# psoc4200bl register map
Vendor: Cypress Semiconductor; Series: PSoC4200BL; File version: 1.0
CPU: CM0 r0p1, little endian, no MPU, no FPU, 2 interrupt priority bits
Registers are 32-bit, read-write, reset 0x0 unless marked. A register's access mark holds for its fields unless they carry their own. Offsets are from the block's base; [hi:lo] are bit positions; lines under a group give offsets from that group.

## BLE (part 5 of 5) — Bluetooth Low Energy Subsystem
Base 0x402E0000
0xF000 BLESS group — Bluetooth Low Energy Subsystem Miscellaneous
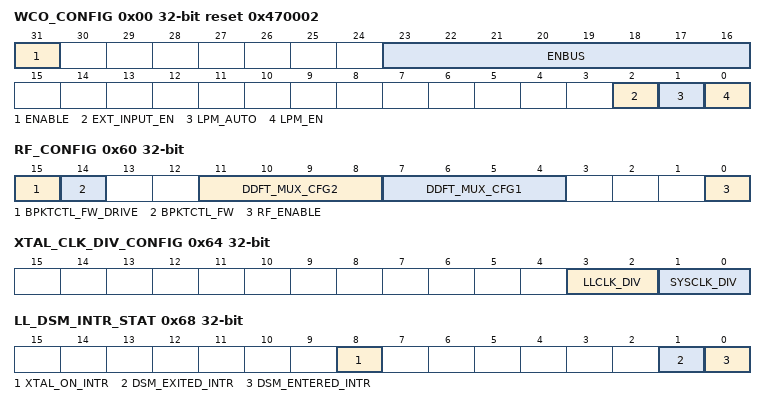
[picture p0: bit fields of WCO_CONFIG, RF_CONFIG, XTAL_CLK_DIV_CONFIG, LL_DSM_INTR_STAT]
  0x00 WCO_CONFIG reset 0x470002 — WCO Configuration Register
    [31] ENABLE — Master enable for WCO oscillator
    [23:16] ENBUS — Test Mode Control bits enbus[7] - N/A enbus[6] - 1=enable both primary Beta Multipliers enbus[5] - N/A enbus[4] - 1=enable digital oscillator detect enbus[3] - Load Resistor Control enbus[2] - Load Resistor Control enbus[1] - Load Resistor Control enbus[0] - Load Resistor Control
    [2] EXT_INPUT_EN — Disables the load resistor and allows external clock input for pad_xin
    [1] LPM_AUTO — Automatically control low power mode (only relevant when LPM_EN=0): 0: Do not enter low power mode (LPM) in DeepSleep 1: Enter low power mode (LPM) in DeepSleep This bit is not functional and should be set to 0, While entering System Deepsleep Mode, do the following before executing WFI IOW BLESS.WCO_TRIM.XGM = 3'b010 IOW BLESS.WCO_TRIM.LPM_GM = 2'b10 IOW BLESS.WCO_CONFIG.LPM_EN = 1'b1 While existing from System Deepsleep Mode, do the following before executing ISR IOW BLESS.WCO_CONFIG.LPM_EN = 1'b0 IOW BLESS.WCO_TRIM.XGM = 3'b001 IOW BLESS.WCO_TRIM.LPM_GM = 2'b01
    [0] LPM_EN — Force block into Low Power Mode: 0: Do not force low power mode (LPM) on 1: Force low power mode (LPM) on
  0x04 WCO_STATUS ro
    [0] OUT_BLNK_A — Indicates that WCO clock has transitioned- This bit is intended for Test Mode Only and is not a reliable indicator.
  0x60 RF_CONFIG — Radio configuration register
    [15] BPKTCTL_FW_DRIVE — Enabled FW drives BLERD bpkctl for radio standalone testing
    [14] BPKTCTL_FW — FW drives BLERD bpktctl if this register bit 15 enabled
    [11:8] DDFT_MUX_CFG2 — dbg_mux_pin2 selection, combine with BLERD and BLESS 4'h0 dbg_pin_mux_2_rd 4'h1 rxdata (RD output) 4'b2 ll_decode_rx_data (llh_cy_asic output) 4'h3 dbus_tx_en (llh_cy_asic output) 4'h4 fw_clk_en (pwr_ctrl_top output) 4'h5 interrupt_ll_n (llh_cy_asic output) 4'h6 ll_st_sm (llh is in SM ) 4'h7 ll_st_dsm (llh is in DSM) 4'he clk_gate_en_xtal (RD eco xtal clock gater enable) 4'hf bb_xo_amp_detect_dft_mux (RD output)
    [7:4] DDFT_MUX_CFG1 — dbg_mux_pin1 selection, combine with BLERD and BLESS 4'h0 dbg_pin_mux_1_rd (RD output) 4'h1 rxclk (RD output) 4'h2 bpktctl_to_rd (RD input) 4'h3 dbus_rx_en (llh_cy_asic output) 4'h4 hw_clk_en (pwr_ctrl_top) 4'h5 clk_switch_to_sysclk (pwr_ctrl_top) 4'h6 ll_clk_en_sync (LL global clock enable from BLESS reg synced) 4'h7 dsm_entry_stat (llh_cy_asic output) 4'h8 ll_dsm_xo_on (LL in DSM, RD XO enabled) 4'h9 ll_dsm_xo_off (LL in DSM, RD XO disabled) 4'hf delayed_bg_en (m0s8bless_misc_dpslp_top output vs LS to s8blerf)
    [0] RF_ENABLE — Enables the RF oscillator band gap. 1: band gap is enabled 0: band gap is disabled
  0x64 XTAL_CLK_DIV_CONFIG — Crystal clock divider configuration register
    [3:2] LLCLK_DIV — Link Layer clock pre-divider value. The 24 MHz crystal clock is divided to generate the Link Layer clock. 0: NO_DIV: LLCLK= XTALCLK/1 1: DIV_BY_2: LLCLK= XTALCLK/2 2: DIV_BY_4: LLCLK= XTALCLK/4 3: DIV_BY_8: LLCLK= XTALCLK/8
    [1:0] SYSCLK_DIV — System clock pre-divider value. The 24 MHz crystal clock is divided to generate the system clock. 0: NO_DIV: SYSCLK= XTALCLK/1 1: DIV_BY_2: SYSCLK= XTALCLK/2 2: DIV_BY_4: SYSCLK= XTALCLK/4 3: DIV_BY_8: SYSCLK= XTALCLK/8
  0x68 LL_DSM_INTR_STAT — Link Layer interrupt status register
    [8] XTAL_ON_INTR — enabled crystal stable signal rising edge interrupt. The interrupt can be cleared by writing one into this location.
    [1] DSM_EXITED_INTR — On a firmware request to LL to exit from Deep Sleep Mode, working on LF clock, LL transitions from Deep Sleep Mode and asserts this interrupt when the Deep Sleep clock gater is turned ON. The interrupt can be cleared by writing one into this location.
    [0] DSM_ENTERED_INTR — On a firmware request to LL to enter into state machine, working on LF clock, LL transitions into Deep Sleep Mode and asserts this interrupt. The interrupt can be cleared by writing one into this location.
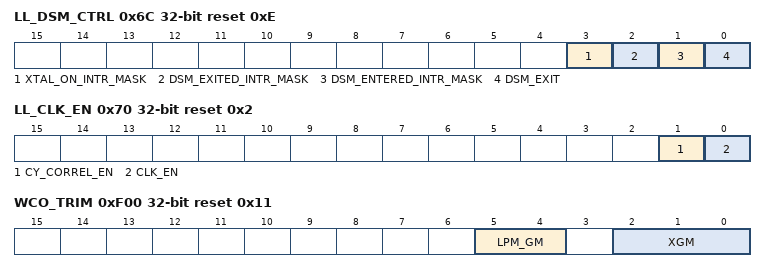
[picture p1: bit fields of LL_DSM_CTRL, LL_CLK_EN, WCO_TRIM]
  0x6C LL_DSM_CTRL reset 0xE — Link Layer state machine control register
    [3] XTAL_ON_INTR_MASK — Masks the Crystal Stable Interrupt, when disabled.
    [2] DSM_EXITED_INTR_MASK — Masks the DSM Exited Interrupt, when disabled.
    [1] DSM_ENTERED_INTR_MASK — Masks the DSM Entered Interrupt, when disabled.
    [0] DSM_EXIT — When the Link Layer is in Deep Sleep Mode, firmware can set this bit to wake the Link Layer.
  0x70 LL_CLK_EN reset 0x2 — Link Layer primary clock enable
    [1] CY_CORREL_EN — Set this bit 1 to enable Cypress Correlator logic to bypass MT logic
    [0] CLK_EN — Set this bit 1 to enable the clock to Link Layer.
  0x74 LF_CLK_CTRL — BLESS LF clock control
    [0] DISABLE_LF_CLK — When set to 1, gates the LF clock input to the Link Layer. Ths is done for extended DSM mode where the DSM state machine needs to be forzen to prevent a default auto exit.
  0xF00 WCO_TRIM reset 0x11
    [5:4] LPM_GM — GM setting for LPM (bandwidth = DC/ms)
    [2:0] XGM — Amplifier GM setting 0x0 - 3370 nA 0x1 - 2620 nA 0x2 - 2250 nA 0x3 - 1500 nA 0x4 - 1870 nA 0x5 - 1120 nA 0x6 - 750 nA 0x7 - 0 nA
